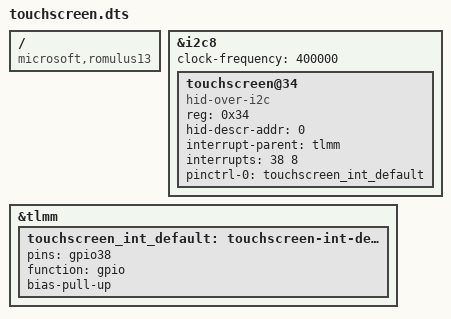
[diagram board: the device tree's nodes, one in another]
/dts-v1/;
/plugin/;
/ { compatible = "microsoft,romulus13", "qcom,x1e80100"; };
&i2c8 {
    clock-frequency = <400000>;
    status = "okay";
    touchscreen@34 {
        compatible = "hid-over-i2c";
        reg = <0x34>;
        hid-descr-addr = <0>;
        interrupt-parent = <&tlmm>;
        interrupts = <38 8>;
        pinctrl-0 = <&touchscreen_int_default>;
        pinctrl-names = "default";
    };
};
&tlmm {
    touchscreen_int_default: touchscreen-int-default-state {
        pins = "gpio38";
        function = "gpio";
        bias-pull-up;
    };
};
